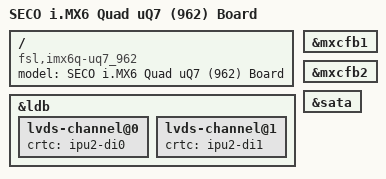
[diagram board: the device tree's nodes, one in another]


/dts-v1/;

#include "imx6q.dtsi"
#include "imx6qdl-seco_uq7_962.dtsi"
#include "imx6qdl-seco_lvds_display.dtsi"

/ {
	model = "SECO i.MX6 Quad uQ7 (962) Board";
	compatible = "fsl,imx6q-uq7_962", "fsl,imx6q";
};

&ldb {
	lvds-channel@0 {
		crtc = "ipu2-di0";
	};

	lvds-channel@1 {
		crtc = "ipu2-di1";
	};
};

&mxcfb1 {
	status = "okay";
};

&mxcfb2 {
	status = "okay";
};

//&mxcfb3 {
//	status = "okay";
//};
//
//&mxcfb4 {
//	status = "okay";
//};

&sata {
	status = "okay";
};
